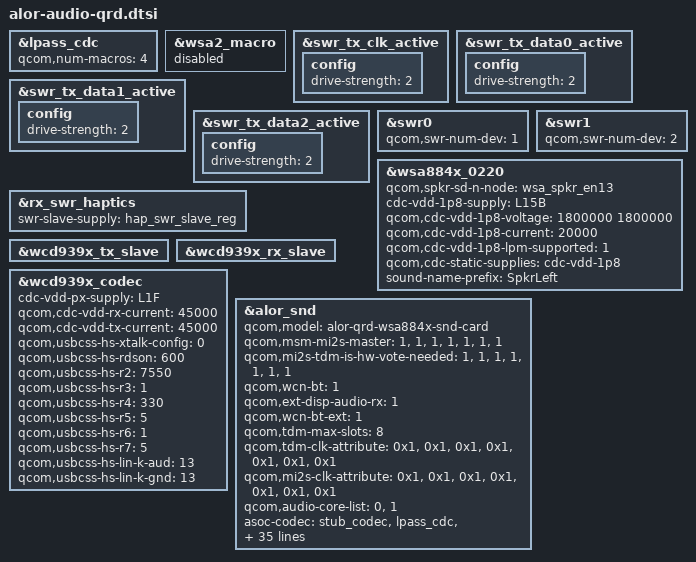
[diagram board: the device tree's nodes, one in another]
//
/* Copyright (c) Qualcomm Technologies, Inc. and/or its subsidiaries.
 * SPDX-License-Identifier: BSD-3-Clause-Clear.
 */

#include "alor-lpi.dtsi"
#include "lpass-audio-cdc-1.0.dtsi"
#include "lpass-audio-bt-swr.dtsi"
#include "lpass-cdc-gpio.dtsi"
#include "alor-audio-lpass-reg.dtsi"
#include "wsa884x.dtsi"
#include "wcd939x.dtsi"

&lpass_cdc {
	qcom,num-macros = <4>;
};

&wsa2_macro {
	status = "disabled";
};

&swr_tx_clk_active {
	config {
		drive-strength = <2>;
	};
};

&swr_tx_data0_active {
	config {
		drive-strength = <2>;
	};
};

&swr_tx_data1_active {
	config {
		drive-strength = <2>;
	};
};

&swr_tx_data2_active {
	config {
		drive-strength = <2>;
	};
};

&swr0{
	status = "okay";
	qcom,swr-num-dev = <1>;
};

&swr1 {
	qcom,swr-num-dev = <2>;
};

&wsa884x_0220 {
	status = "okay";
	qcom,spkr-sd-n-node = <&wsa_spkr_en13>;
	cdc-vdd-1p8-supply = <&L15B>;
	qcom,cdc-vdd-1p8-voltage = <1800000 1800000>;
	qcom,cdc-vdd-1p8-current = <20000>;
	qcom,cdc-vdd-1p8-lpm-supported = <1>;
	qcom,cdc-static-supplies = "cdc-vdd-1p8";
	sound-name-prefix = "SpkrLeft";
};

&rx_swr_haptics {
	status = "okay";
	swr-slave-supply = <&hap_swr_slave_reg>;
};


&wcd939x_tx_slave {
	status = "okay";
};

&wcd939x_rx_slave {
	status = "okay";
};

&wcd939x_codec {
	status = "okay";
	/* 0 for digital crosstalk disabled,
	 * 1 for digital crosstalk with local sensed a-xtalk enabled, and
	 * 2 for digital crosstalk with remote sensed a-xtalk enabled.
	 */
	cdc-vdd-px-supply = <&L1F>;
	qcom,cdc-vdd-rx-current = <45000>;
	qcom,cdc-vdd-tx-current = <45000>;
	qcom,usbcss-hs-xtalk-config = <0>;
	qcom,usbcss-hs-rdson = <600>;
	qcom,usbcss-hs-r2 = <7550>;
	qcom,usbcss-hs-r3 = <1>;
	qcom,usbcss-hs-r4 = <330>;
	qcom,usbcss-hs-r5 = <5>;
	qcom,usbcss-hs-r6 = <1>;
	qcom,usbcss-hs-r7 = <5>;
	qcom,usbcss-hs-lin-k-aud = <13>;
	qcom,usbcss-hs-lin-k-gnd = <13>;

};

&alor_snd {
	qcom,model = "alor-qrd-wsa884x-snd-card";
	qcom,msm-mi2s-master = <1>, <1>, <1>, <1>, <1>, <1>, <1>;
	qcom,mi2s-tdm-is-hw-vote-needed = <1>, <1>, <1>, <1>, <1>, <1>, <1>;
	qcom,wcn-bt = <1>;
	qcom,ext-disp-audio-rx = <1>;
	qcom,wcn-bt-ext = <1>;
	qcom,tdm-max-slots = <8>;
	qcom,tdm-clk-attribute = <0x1>, <0x1>, <0x1>, <0x1>, <0x1>, <0x1>, <0x1>;
	qcom,mi2s-clk-attribute = <0x1>, <0x1>, <0x1>, <0x1>, <0x1>, <0x1>, <0x1>;
	qcom,audio-core-list = <0>, <1>;
	asoc-codec  = <&stub_codec>, <&lpass_cdc>,
			<&wcd939x_codec>, <&rx_swr_haptics>,
			<&wsa884x_0220>;
	asoc-codec-names = "msm-stub-codec.1", "lpass-cdc",
			"wcd939x_codec", "swr-haptics",
			"wsa-codec1";
	qcom,wsa-max-devs = <1>;
	qcom,audio-routing =
		"AMIC1", "Analog Mic1",
		"AMIC1", "MIC BIAS1",
		"AMIC2", "Analog Mic2",
		"AMIC2", "MIC BIAS2",
		"AMIC3", "Analog Mic3",
		"AMIC3", "MIC BIAS3",
		"AMIC4", "Analog Mic4",
		"AMIC4", "MIC BIAS3",
		"AMIC5", "Analog Mic5",
		"AMIC5", "MIC BIAS4",
		"VA AMIC1", "Analog Mic1",
		"VA AMIC1", "VA MIC BIAS1",
		"VA AMIC2", "Analog Mic2",
		"VA AMIC2", "VA MIC BIAS2",
		"VA AMIC3", "Analog Mic3",
		"VA AMIC3", "VA MIC BIAS3",
		"VA AMIC4", "Analog Mic4",
		"VA AMIC4", "VA MIC BIAS3",
		"VA AMIC5", "Analog Mic5",
		"VA AMIC5", "VA MIC BIAS4",
		"IN1_HPHL", "HPHL_OUT",
		"IN2_HPHR", "HPHR_OUT",
		"IN3_EAR", "AUX_OUT",
		"HAP_IN", "PCM_OUT",
		"WSA SRC0_INP", "SRC0",
		"WSA_TX DEC0_INP", "TX DEC0 MUX",
		"WSA_TX DEC1_INP", "TX DEC1 MUX",
		"RX_TX DEC0_INP", "TX DEC0 MUX",
		"RX_TX DEC1_INP", "TX DEC1 MUX",
		"RX_TX DEC2_INP", "TX DEC2 MUX",
		"RX_TX DEC3_INP", "TX DEC3 MUX",
		"SpkrLeft IN", "WSA_SPK1 OUT",
		"TX SWR_INPUT", "WCD_TX_OUTPUT",
		"VA SWR_INPUT", "VA_SWR_CLK",
		"VA SWR_INPUT", "WCD_TX_OUTPUT",
		"VA_AIF1 CAP", "VA_SWR_CLK",
		"VA_AIF2 CAP", "VA_SWR_CLK",
		"VA_AIF3 CAP", "VA_SWR_CLK";

	qcom,msm-mbhc-hs-mic-max-threshold-mv = <1670>;
	qcom,msm-mbhc-usbc-audio-supported = <1>;
	qcom,msm-mbhc-hphl-swh = <0>;
	qcom,msm-mbhc-gnd-swh = <0>;

	wcd939x-i2c-handle = <&wcd_usbss>;
	qcom,msm_audio_ssr_devs = <&audio_gpr>, <&lpi_tlmm>,
			<&lpass_cdc>, <&lpass_bt_swr>;
		/*
		 * ====================
		 * UPD backend - WSA
		 * ====================
		 *
		 * Mute/Unmute the interpolator
		 * ------------------------------
		 * Register: LPASS_WSA_CDC_RX0_RX_PATH_MIX_CTL - 0x6B00418
		 *
		 * Send control commands to the peripheral from the soundwire controller
		 * -----------------------------------------------------------------------
		 * Register: LPASS_WSA_SWR_MSTR_WSA_SWRM_CPUn_CMD_FIFO_WR_CMD - 0x6B14020
		 *
		 * Enable/Disable ear piece
		 * --------------------------
		 * Register: DIG_CTRL0_PA_FSM_EN - 0x3430
		 *
		 *
		 *	qcom,upd_backends_used = "wsa";
		 *	qcom,upd_lpass_reg_addr = <0x6B00418 0x6B14020>;
		 *	qcom,upd_ear_pa_reg_addr = <0x3430>;
		/*
		* ====================
		* UPD backend - WCD
		* ====================
		*
		* Mute/Unmute the interpolator
		* ------------------------------
		* Register: LPASS_WCD_CDC_RX0_RX_PATH_MIX_CTL - 0x6AC0418
		*
		* Send control commands to the wcd from the soundwire controller
		* ----------------------------------------------------------------
		* Register: LPASS_WCD_SWR_MSTR_WSA_SWRM_CPUn_CMD_FIFO_WR_CMD - 0x7634020
		*
		* Enable/Disable ear piece
		* --------------------------
		* Register: DIG_CTRL0_PA_FSM_EN - 0x300A
		*
		*/
		/*
		* qcom,upd_backends_used = "wcd";
		* qcom,upd_lpass_reg_addr = <0x6AC0418 0x7634020>;
		* qcom,upd_ear_pa_reg_addr = <0x300A>;
		*/
};
